# MKE02Z2 register map
File version: 1.6
Registers are 32-bit, read-write, reset 0x0 unless marked. A register's access mark holds for its fields unless they carry their own. Offsets are from the block's base; [hi:lo] are bit positions.

## KBI0 — Keyboard interrupts
Base 0x40079000; register names take the prefix KBI0_
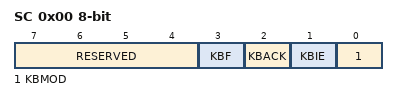
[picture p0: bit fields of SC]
0x00 SC 8-bit — KBI Status and Control Register
  [7:4] RESERVED ro
  [3] KBF ro — KBI Interrupt Flag
    0=KBI interrupt request not detected; 1=KBI interrupt request detected
  [2] KBACK wo — KBI Acknowledge
  [1] KBIE — KBI Interrupt Enable
    0=KBI interrupt not enabled; 1=KBI interrupt enabled
  [0] KBMOD — KBI Detection Mode
    0=Keyboard detects edges only; 1=Keyboard detects both edges and levels
0x01 PE 8-bit — KBIx Pin Enable Register
  [7:0] KBIPE — KBI Pin Enables
    0=Pin is not enabled as KBI interrupt; 1=Pin is enabled as KBI interrupt
0x02 ES 8-bit — KBIx Edge Select Register
  [7:0] KBEDG — KBI Edge Selects
    0=Falling edge/low level; 1=Rising edge/high level

## KBI1 — Keyboard interrupts
Base 0x4007A000; register names take the prefix KBI1_
Registers as KBI0.

## PMC — Power management
Base 0x4007D000; register names take the prefix PMC_
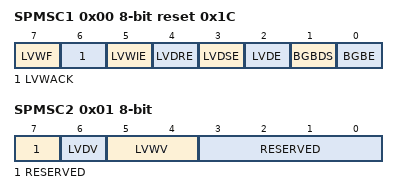
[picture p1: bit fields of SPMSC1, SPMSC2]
0x00 SPMSC1 8-bit reset 0x1C — System Power Management Status and Control 1 Register
  [7] LVWF ro — Low-Voltage Warning Flag
    0=Low-voltage warning is not present; 1=Low-voltage warning is present or was present
  [6] LVWACK wo — Low-Voltage Warning Acknowledge
  [5] LVWIE — Low-Voltage Warning Interrupt Enable
    0=Hardware interrupt is disabled (use polling); 1=Requests a hardware interrupt when LVWF = 1
  [4] LVDRE — Low-Voltage Detect Reset Enable
    0=LVD events do not generate hardware resets; 1=Forces an MCU reset when an enabled low-voltage detect event occurs
  [3] LVDSE — Low-Voltage Detect Stop Enable
    0=Low-voltage detect is disabled during Stop mode; 1=Low-voltage detect is enabled during Stop mode
  [2] LVDE — Low-Voltage Detect Enable
    0=LVD logic is disabled; 1=LVD logic is enabled
  [1] BGBDS — Bandgap Buffer Drive Select
    0=Bandgap buffer is enabled in low-drive mode if BGBE = 1; 1=Bandgap buffer is enabled in high-drive mode if BGBE = 1
  [0] BGBE — Bandgap Buffer Enable
    0=Bandgap buffer is disabled; 1=Bandgap buffer is enabled
0x01 SPMSC2 8-bit — System Power Management Status and Control 2 Register
  [7] RESERVED ro
  [6] LVDV — Low-Voltage Detect Voltage Select
    0=Low trip point is selected (VLVD = VLVDL); 1=High trip point is selected (VLVD = VLVDH)
  [5:4] LVWV — Low-Voltage Warning Voltage Select
    0=Low trip point is selected (VLVW = VLVW1); 1=Middle 1 trip point is selected (VLVW = VLVW2); 2=Middle 2 trip point is selected (VLVW = VLVW3); 3=High trip point is selected (VLVW = VLVW4)
  [3:0] RESERVED ro

## PTA — General Purpose Input/Output
Base 0x400FF000; register names take the prefix GPIOA_
0x00 PDOR — Port Data Output Register
  [31:0] PDO — Port Data Output
    0=Logic level 0 is driven on pin, provided pin is configured for general-purpose output; 1=Logic level 1 is driven on pin, provided pin is configured for general-purpose output
0x04 PSOR wo — Port Set Output Register
  [31:0] PTSO — Port Set Output
    0=Corresponding bit in PDORn does not change; 1=Corresponding bit in PDORn is set to logic 1
0x08 PCOR wo — Port Clear Output Register
  [31:0] PTCO — Port Clear Output
    0=Corresponding bit in PDORn does not change; 1=Corresponding bit in PDORn is cleared to logic 0
0x0C PTOR wo — Port Toggle Output Register
  [31:0] PTTO — Port Toggle Output
    0=Corresponding bit in PDORn does not change; 1=Corresponding bit in PDORn is set to the inverse of its existing logic state
0x10 PDIR ro — Port Data Input Register
  [31:0] PDI — Port Data Input
    0=Pin logic level is logic 0, or is not configured for use by digital function; 1=Pin logic level is logic 1
0x14 PDDR — Port Data Direction Register
  [31:0] PDD — Port Data Direction
    0=Pin is configured as general-purpose input, for the GPIO function. The pin will be high-Z if the port input is disabled in GPIOx_PIDR register.; 1=Pin is configured as general-purpose output, for the GPIO function
0x18 PIDR reset 0xFFFFFFFF — Port Input Disable Register
  [31:0] PID — Port Input Disable
    0=Pin is configured for General Purpose Input, provided the pin is configured for any digital function; 1=Pin is not configured as General Purpose Input.Corresponding Pin Data Input Register bit will read zero

## PTB — General Purpose Input/Output
Base 0x400FF040; register names take the prefix GPIOB_
Registers as PTA.

## FPTA — General Purpose Input/Output
Base 0xF8000000; register names take the prefix FGPIOA_
Registers as PTA; these are added or differ:
0x14 PDDR — Port Data Direction Register
  [31:0] PDD — Port Data Direction
    0=Pin is configured as general-purpose input, for the GPIO function. The pin will be high-Z if the port input is disabled in FPIOx_PIDR register.; 1=Pin is configured as general-purpose output, for the GPIO function

## FPTB — General Purpose Input/Output
Base 0xF8000040; register names take the prefix FGPIOB_
Registers as FPTA.

## MCM — Core Platform Miscellaneous Control Module
Base 0xF0003000; register names take the prefix MCM_
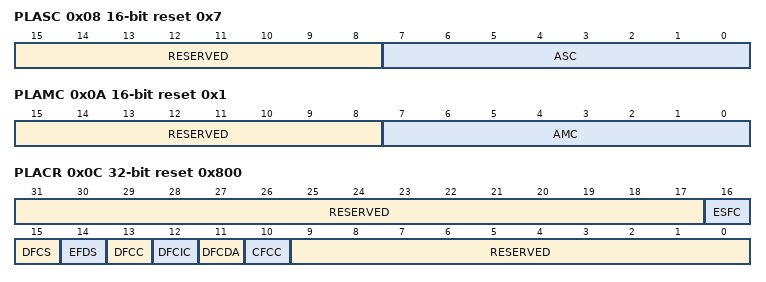
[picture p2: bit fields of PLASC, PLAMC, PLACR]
0x08 PLASC 16-bit ro reset 0x7 — Crossbar Switch (AXBS) Slave Configuration
  [15:8] RESERVED
  [7:0] ASC — Each bit in the ASC field indicates whether there is a corresponding connection to the crossbar switch's slave input port.
    0=A bus slave connection to AXBS input port n is absent; 1=A bus slave connection to AXBS input port n is present
0x0A PLAMC 16-bit ro reset 0x1 — Crossbar Switch (AXBS) Master Configuration
  [15:8] RESERVED
  [7:0] AMC — Each bit in the AMC field indicates whether there is a corresponding connection to the AXBS master input port.
    0=A bus master connection to AXBS input port n is absent; 1=A bus master connection to AXBS input port n is present
0x0C PLACR reset 0x800 — Platform Control Register
  [31:17] RESERVED ro
  [16] ESFC — Enable Stalling Flash Controller
    0=Disable stalling flash controller when flash is busy; 1=Enable stalling flash controller when flash is busy
  [15] DFCS — Disable Flash Controller Speculation
    0=Enable flash controller speculation; 1=Disable flash controller speculation
  [14] EFDS — Enable Flash Data Speculation
    0=Disable flash data speculation; 1=Enable flash data speculation
  [13] DFCC — Disable Flash Controller Cache
    0=Enable flash controller cache; 1=Disable flash controller cache
  [12] DFCIC — Disable Flash Controller Instruction Caching
    0=Enable flash controller instruction caching; 1=Disable flash controller instruction caching
  [11] DFCDA — Disable Flash Controller Data Caching
    0=Enable flash controller data caching; 1=Disable flash controller data caching
  [10] CFCC wo — Clear Flash Controller Cache
  [9:0] RESERVED ro
